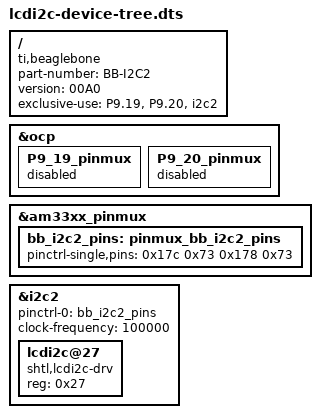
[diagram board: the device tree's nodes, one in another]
/dts-v1/;
/plugin/;

/ {
	compatible = "ti,beaglebone", "ti,beaglebone-black", "ti,beaglebone-green";

	// identification
	part-number = "BB-I2C2";
	version = "00A0";

	// resources this cape uses
	exclusive-use =
		"P9.19",	// i2c2_sda
		"P9.20",	// i2c2_scl

		"i2c2";		// hardware ip used

	/*
	 * Free up the pins used by the cape from the pinmux helpers.
	 */
	fragment@0 {
		target = <&ocp>;
		__overlay__ {
			P9_19_pinmux { status = "disabled"; };	/* i2c2_scl */
			P9_20_pinmux { status = "disabled"; };	/* i2c2_sda */
		};
	};

	fragment@1 {
		target = <&am33xx_pinmux>;
		__overlay__ {
			bb_i2c2_pins: pinmux_bb_i2c2_pins {
				pinctrl-single,pins = <
					0x17c 0x73	/* i2c2_sda, SLEWCTRL_SLOW | INPUT_PULLUP | MODE3 */
					0x178 0x73	/* i2c2_scl, SLEWCTRL_SLOW | INPUT_PULLUP | MODE3 */
				>;
			};
		};
	};

	fragment@2 {
		target = <&i2c2>;
		__overlay__ {
			status = "okay";
			pinctrl-names = "default";
			pinctrl-0 = <&bb_i2c2_pins>;

			/* this is the configuration part */
			clock-frequency = <100000>;

			#address-cells = <1>;
			#size-cells = <0>;

			/* i2c device */

			lcdi2c@27 {
				compatible = "shtl,lcdi2c-drv";
				status = "okay";
				reg = <0x27>;
			};
		};
	};
};
